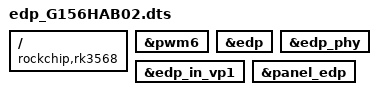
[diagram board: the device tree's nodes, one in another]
/dts-v1/;
/plugin/;
/ {
	compatible = "rockchip,rk3568";

	fragment@0 {
		target = <&pwm6>;
		__overlay__ {
			status = "okay";
		};
	};
	fragment@1 {
		target = <&edp>;
		__overlay__ {
			status = "okay";
		};
	};
	fragment@2 {
		target = <&edp_phy>;
		__overlay__ {
			status = "okay";
		};
	};
	fragment@3 {
		target = <&edp_in_vp1>;
		__overlay__ {
			status = "okay";
		};
	};
	fragment@4 {
		target = <&panel_edp>;
		__overlay__ {
			status = "okay";
		};
	};
};
